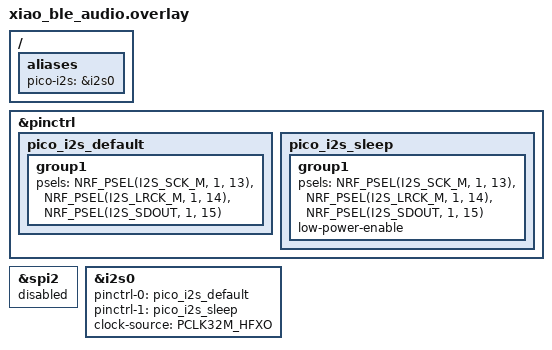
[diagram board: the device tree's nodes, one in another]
/* Optional MAX98357A overlay. Existing OLED and D0/D1 controls are included. */
#include "xiao_ble_ssd1306.overlay"
#include <zephyr/dt-bindings/pinctrl/nrf-pinctrl.h>
&pinctrl {
    pico_i2s_default: pico_i2s_default {
        group1 {
            psels = <NRF_PSEL(I2S_SCK_M, 1, 13)>,
                    <NRF_PSEL(I2S_LRCK_M, 1, 14)>,
                    <NRF_PSEL(I2S_SDOUT, 1, 15)>;
        };
    };
    pico_i2s_sleep: pico_i2s_sleep {
        group1 {
            psels = <NRF_PSEL(I2S_SCK_M, 1, 13)>,
                    <NRF_PSEL(I2S_LRCK_M, 1, 14)>,
                    <NRF_PSEL(I2S_SDOUT, 1, 15)>;
            low-power-enable;
        };
    };
};
&spi2 { status = "disabled"; };
&i2s0 {
    status = "okay";
    pinctrl-0 = <&pico_i2s_default>;
    pinctrl-1 = <&pico_i2s_sleep>;
    pinctrl-names = "default", "sleep";
    clock-source = "PCLK32M_HFXO";
};
/ { aliases { pico-i2s = &i2s0; }; };
